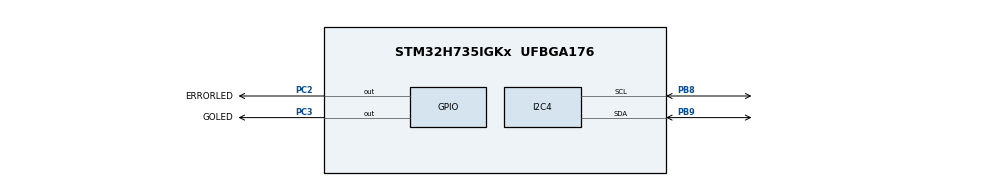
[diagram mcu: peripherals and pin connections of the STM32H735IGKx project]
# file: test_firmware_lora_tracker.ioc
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Mcu.Family=STM32H7
RCC.PLLSourceVirtual=RCC_PLLSOURCE_HSE
PC15-OSC32_OUT.Mode=LSE-External-Oscillator
PH0-OSC_IN.Signal=RCC_OSC_IN
RCC.CortexFreq_Value=550000000
RCC.DIVQ1=4
I2C4.Speed=100
RCC.HPRE=RCC_HCLK_DIV2
RCC.PLLFRACN=0
PC2.Signal=GPIO_Output
RCC.D2PPRE2=RCC_APB2_DIV2
RCC.D2PPRE1=RCC_APB1_DIV2
RCC.DIVP2=5
RCC.DIVP1=1
RCC.PLL2FRACN=0
PC14-OSC32_IN.Signal=RCC_OSC32_IN
RCC.SYSCLKSource=RCC_SYSCLKSOURCE_PLLCLK
ProjectManager.StackSize=0x400
ProjectManager.TargetToolchain=STM32CubeIDE
I2C4.Timing=0x20B0C8FF
RCC.HCLKFreq_Value=275000000
PB9.Mode=I2C
RCC.DIVN2=80
RCC.DIVN1=110
PC3.Signal=GPIO_Output
RCC.USBFreq_Value=48000000
I2C4.Analog_Filter=I2C_ANALOGFILTER_DISABLE
PC15-OSC32_OUT.Signal=RCC_OSC32_OUT
PH0-OSC_IN.Mode=HSE-External-Clock-Source
RCC.USBCLockSelection=RCC_USBCLKSOURCE_HSI48
board=STM32H735G-DK
RCC.DIVM2=5
RCC.DIVM1=5
RCC.APB2Freq_Value=137500000
PC14-OSC32_IN.Mode=LSE-External-Oscillator
RCC.ADCFreq_Value=80000000
Mcu.Name=STM32H735IGKx
RCC.APB3Freq_Value=137500000
RCC.SYSCLKFreq_VALUE=550000000
Mcu.Package=UFBGA176
PB9.Signal=I2C4_SDA
RCC.PLL3FRACN=0
RCC.D1PPRE=RCC_APB3_DIV2
ProjectManager.HeapSize=0x200
NVIC.PriorityGroup=NVIC_PRIORITYGROUP_4
PB8.Mode=I2C
RCC.APB4Freq_Value=137500000
PB8.Signal=I2C4_SCL
PC3.GPIO_Label=GOLED
RCC.D3PPRE=RCC_APB4_DIV2
RCC.APB1Freq_Value=137500000
PC2.GPIO_Label=ERRORLED

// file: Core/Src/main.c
/* USER CODE BEGIN Header */
/**
  ******************************************************************************
  * @file           : main.c
  * @brief          : Main program body
  ******************************************************************************
  * @attention
  *
  * <h2><center>&copy; Copyright (c) 2021 STMicroelectronics.
  * All rights reserved.</center></h2>
  *
  * This software component is licensed by ST under BSD 3-Clause license,
  * the "License"; You may not use this file except in compliance with the
  * License. You may obtain a copy of the License at:
  *                        opensource.org/licenses/BSD-3-Clause
  *
  ******************************************************************************
  */
/* USER CODE END Header */
#include "main.h"

/* USER CODE BEGIN Includes */
#include <lis3d.h>

/* USER CODE END Includes */

I2C_HandleTypeDef hi2c4;

void SystemClock_Config(void);
static void MX_GPIO_Init(void);
static void MX_I2C4_Init(void);

int main(void)
{

  /* MCU Configuration--------------------------------------------------------*/

  /* Reset of all peripherals, Initializes the Flash interface and the Systick. */
  HAL_Init();

  /* Configure the system clock */
  SystemClock_Config();

  /* Initialize all configured peripherals */
  MX_GPIO_Init();
  MX_I2C4_Init();

  /* Infinite loop */
  /* USER CODE BEGIN WHILE */
  while (1)
  {
	  int statuscode=8;
	  statuscode = SanityCheck();
	  HAL_Delay(1000);

    /* USER CODE END WHILE */

  }
}

void SystemClock_Config(void)
{
  RCC_OscInitTypeDef RCC_OscInitStruct = {0};
  RCC_ClkInitTypeDef RCC_ClkInitStruct = {0};

  /** Supply configuration update enable
  */
  HAL_PWREx_ConfigSupply(PWR_DIRECT_SMPS_SUPPLY);
  /** Configure the main internal regulator output voltage
  */
  __HAL_PWR_VOLTAGESCALING_CONFIG(PWR_REGULATOR_VOLTAGE_SCALE0);

  while(!__HAL_PWR_GET_FLAG(PWR_FLAG_VOSRDY)) {}
  /** Initializes the RCC Oscillators according to the specified parameters
  * in the RCC_OscInitTypeDef structure.
  */
  RCC_OscInitStruct.OscillatorType = RCC_OSCILLATORTYPE_HSE;
  RCC_OscInitStruct.HSEState = RCC_HSE_BYPASS;
  RCC_OscInitStruct.PLL.PLLState = RCC_PLL_ON;
  RCC_OscInitStruct.PLL.PLLSource = RCC_PLLSOURCE_HSE;
  RCC_OscInitStruct.PLL.PLLM = 5;
  RCC_OscInitStruct.PLL.PLLN = 110;
  RCC_OscInitStruct.PLL.PLLP = 1;
  RCC_OscInitStruct.PLL.PLLQ = 4;
  RCC_OscInitStruct.PLL.PLLR = 2;
  RCC_OscInitStruct.PLL.PLLRGE = RCC_PLL1VCIRANGE_2;
  RCC_OscInitStruct.PLL.PLLVCOSEL = RCC_PLL1VCOWIDE;
  RCC_OscInitStruct.PLL.PLLFRACN = 0;
  if (HAL_RCC_OscConfig(&RCC_OscInitStruct) != HAL_OK)
  {
    Error_Handler();
  }
  /** Initializes the CPU, AHB and APB buses clocks
  */
  RCC_ClkInitStruct.ClockType = RCC_CLOCKTYPE_HCLK|RCC_CLOCKTYPE_SYSCLK
                              |RCC_CLOCKTYPE_PCLK1|RCC_CLOCKTYPE_PCLK2
                              |RCC_CLOCKTYPE_D3PCLK1|RCC_CLOCKTYPE_D1PCLK1;
  RCC_ClkInitStruct.SYSCLKSource = RCC_SYSCLKSOURCE_PLLCLK;
  RCC_ClkInitStruct.SYSCLKDivider = RCC_SYSCLK_DIV1;
  RCC_ClkInitStruct.AHBCLKDivider = RCC_HCLK_DIV2;
  RCC_ClkInitStruct.APB3CLKDivider = RCC_APB3_DIV2;
  RCC_ClkInitStruct.APB1CLKDivider = RCC_APB1_DIV2;
  RCC_ClkInitStruct.APB2CLKDivider = RCC_APB2_DIV2;
  RCC_ClkInitStruct.APB4CLKDivider = RCC_APB4_DIV2;

  if (HAL_RCC_ClockConfig(&RCC_ClkInitStruct, FLASH_LATENCY_3) != HAL_OK)
  {
    Error_Handler();
  }
}

static void MX_I2C4_Init(void)
{

  hi2c4.Instance = I2C4;
  hi2c4.Init.Timing = 0x20B0C8FF;
  hi2c4.Init.OwnAddress1 = 0;
  hi2c4.Init.AddressingMode = I2C_ADDRESSINGMODE_7BIT;
  hi2c4.Init.DualAddressMode = I2C_DUALADDRESS_DISABLE;
  hi2c4.Init.OwnAddress2 = 0;
  hi2c4.Init.OwnAddress2Masks = I2C_OA2_NOMASK;
  hi2c4.Init.GeneralCallMode = I2C_GENERALCALL_DISABLE;
  hi2c4.Init.NoStretchMode = I2C_NOSTRETCH_DISABLE;
  if (HAL_I2C_Init(&hi2c4) != HAL_OK)
  {
    Error_Handler();
  }
  /** Configure Analogue filter
  */
  if (HAL_I2CEx_ConfigAnalogFilter(&hi2c4, I2C_ANALOGFILTER_DISABLE) != HAL_OK)
  {
    Error_Handler();
  }
  /** Configure Digital filter
  */
  if (HAL_I2CEx_ConfigDigitalFilter(&hi2c4, 0) != HAL_OK)
  {
    Error_Handler();
  }

}

static void MX_GPIO_Init(void)
{
  GPIO_InitTypeDef GPIO_InitStruct = {0};

  /* GPIO Ports Clock Enable */
  __HAL_RCC_GPIOB_CLK_ENABLE();
  __HAL_RCC_GPIOC_CLK_ENABLE();
  __HAL_RCC_GPIOH_CLK_ENABLE();

  /*Configure GPIO pin Output Level */
  HAL_GPIO_WritePin(GPIOC, ERRORLED_Pin|GOLED_Pin, GPIO_PIN_RESET);

  /*Configure GPIO pins : ERRORLED_Pin GOLED_Pin */
  GPIO_InitStruct.Pin = ERRORLED_Pin|GOLED_Pin;
  GPIO_InitStruct.Mode = GPIO_MODE_OUTPUT_PP;
  GPIO_InitStruct.Pull = GPIO_NOPULL;
  GPIO_InitStruct.Speed = GPIO_SPEED_FREQ_LOW;
  HAL_GPIO_Init(GPIOC, &GPIO_InitStruct);

}

void Error_Handler(void)
{
  __disable_irq();
  while (1)
  {
  }
}

/************************ (C) COPYRIGHT STMicroelectronics *****END OF FILE****/
